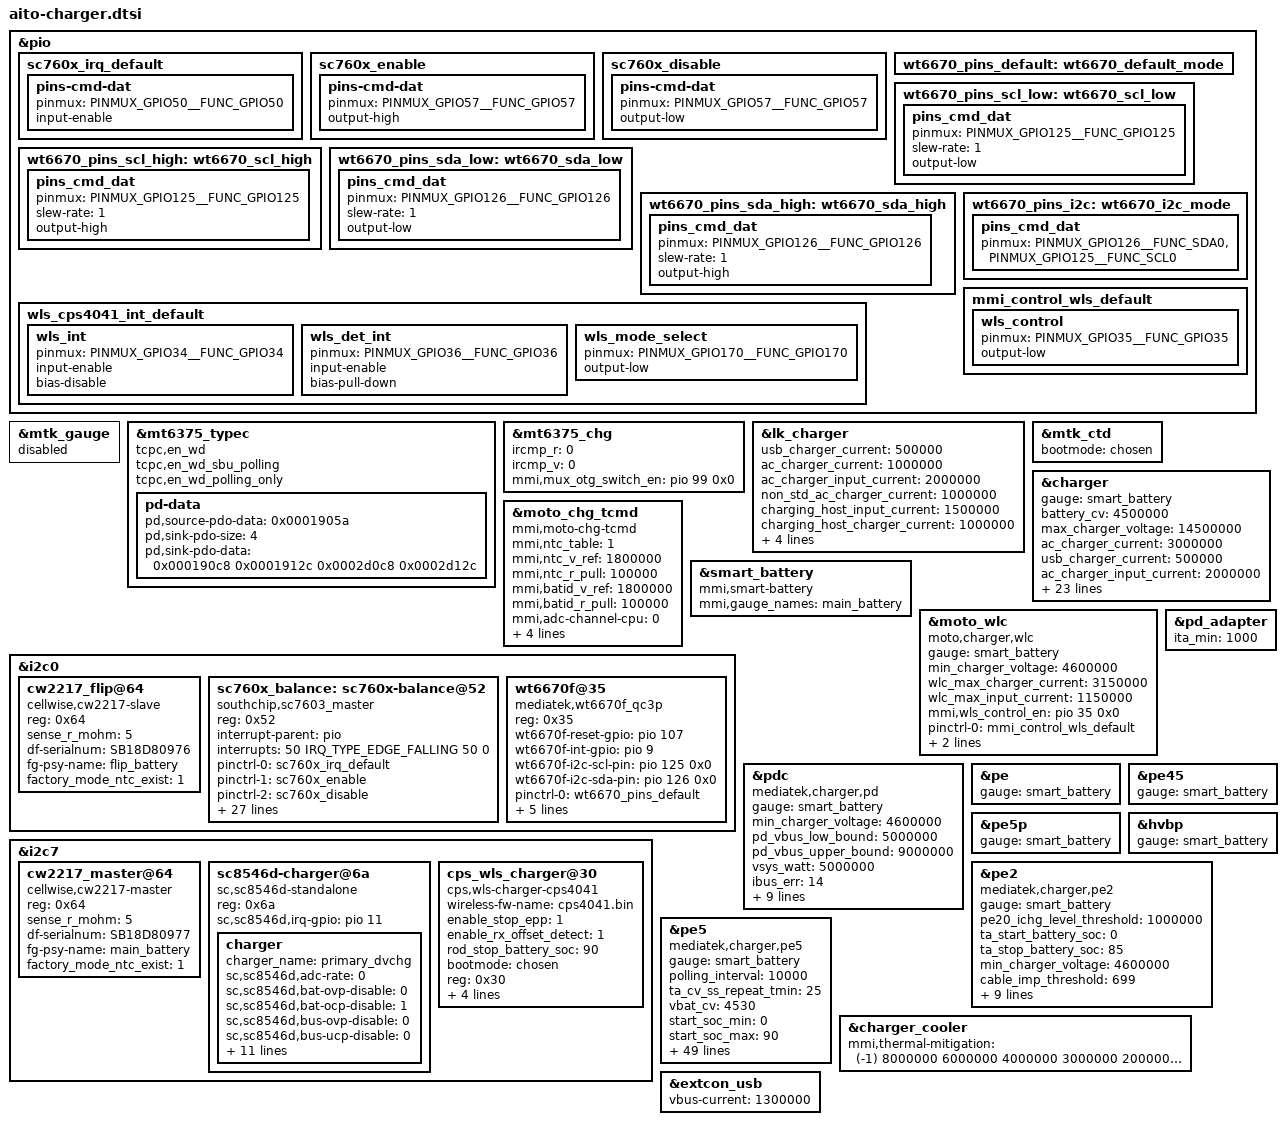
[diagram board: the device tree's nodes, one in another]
/*
 * Copyright (c) 2021 MediaTek Inc.
 *
 * This program is free software; you can redistribute it and/or modify
 * it under the terms of the GNU General Public License version 2 as
 * published by the Free Software Foundation.
 *
 * This program is distributed in the hope that it will be useful,
 * but WITHOUT ANY WARRANTY; without even the implied warranty of
 * MERCHANTABILITY or FITNESS FOR A PARTICULAR PURPOSE.  See the
 * GNU General Public License for more details.
 */
#include <dt-bindings/iio/adc/mediatek,mt6375_auxadc.h>
#include <dt-bindings/iio/adc/mediatek,mt6375_adc.h>
#include <dt-bindings/iio/mt635x-auxadc.h>

&pio {
	sc760x_irq_default: sc760x_irq_default {
		pins-cmd-dat {
			pinmux = <PINMUX_GPIO50__FUNC_GPIO50>;
			input-enable;
		};
	};

	sc760x_enable: sc760x_enable {
		pins-cmd-dat {
			pinmux = <PINMUX_GPIO57__FUNC_GPIO57>;
			output-high;
		};
	};
	sc760x_disable: sc760x_disable {
		pins-cmd-dat {
			pinmux = <PINMUX_GPIO57__FUNC_GPIO57>;
			output-low;
		};
	};

	wt6670_pins_default: wt6670_default_mode {
		};

	wt6670_pins_scl_low: wt6670_scl_low {
		pins_cmd_dat {
			pinmux = <PINMUX_GPIO125__FUNC_GPIO125>;
			slew-rate = <1>;
			output-low;
		};
	};
	wt6670_pins_scl_high: wt6670_scl_high {
		pins_cmd_dat {
			pinmux = <PINMUX_GPIO125__FUNC_GPIO125>;
			slew-rate = <1>;
			output-high;
		};
	};
	wt6670_pins_sda_low: wt6670_sda_low {
		pins_cmd_dat {
			pinmux = <PINMUX_GPIO126__FUNC_GPIO126>;
			slew-rate = <1>;
			output-low;
		};
	};
	wt6670_pins_sda_high: wt6670_sda_high {
		pins_cmd_dat {
			pinmux = <PINMUX_GPIO126__FUNC_GPIO126>;
			slew-rate = <1>;
			output-high;
		};
	};
	wt6670_pins_i2c: wt6670_i2c_mode {
		pins_cmd_dat {
			pinmux = <PINMUX_GPIO126__FUNC_SDA0>,
				<PINMUX_GPIO125__FUNC_SCL0>;
		};
	};

	wls_cps4041_int_default: wls_cps4041_int_default {
		wls_int {
			pinmux = <PINMUX_GPIO34__FUNC_GPIO34>;
			input-enable;
			bias-disable;
		};
		wls_det_int {
			pinmux = <PINMUX_GPIO36__FUNC_GPIO36>;
			input-enable;
			bias-pull-down;
		};
		wls_mode_select {
			pinmux = <PINMUX_GPIO170__FUNC_GPIO170>;
			output-low;
		};
	};

	mmi_control_wls_default: mmi_control_wls_default {
		wls_control {
			pinmux = <PINMUX_GPIO35__FUNC_GPIO35>;
			output-low;
		};
	};
};

&mtk_gauge {
	status = "disabled";
};

&mt6375_typec {
       tcpc,en_wd;
       tcpc,en_wd_sbu_polling;
       tcpc,en_wd_polling_only;
};

&mt6375_chg {
	ircmp_r = <0>;
	ircmp_v = <0>;
};

&lk_charger {
	/* charging current */
	usb_charger_current = <500000>;
	ac_charger_current = <1000000>;
	ac_charger_input_current = <2000000>;
	non_std_ac_charger_current = <1000000>;
	charging_host_input_current = <1500000>;
	charging_host_charger_current = <1000000>;
	pre_charge_current = <400>;

	temp_t4_threshold = <60>;
	boot_battery_voltage = <3500000>;
	/*boot battery voltage when using AC charger*/
	ac_charger_boot_battery_voltage = <3400000>;
};

&mtk_ctd {
	bootmode = <&chosen>;
};

&charger {
	gauge = <&smart_battery>;
	battery_cv = <4500000>;
	max_charger_voltage = <14500000>;
	ac_charger_current = <3000000>;
	usb_charger_current = <500000>;
	ac_charger_input_current = <2000000>;
	charging_host_charger_current = <1500000>;
	/*pe5 && pdc && pe2 && wlc*/
	fast_charging_indicator = <0x10>;
	/*swchg + 1CP*/
	charger_configuration= <3>;

	wireless_factory_max_current = <3000000>;
	wireless_factory_max_input_current = <600000>;

	disable_aicl;

	/* dynamic mivr */
	enable_dynamic_mivr;

	/*mmi config*/
	mmi,typec-rp-max-current = <2000000>;
	mmi,iterm-ma = <461>;
	mmi,mmi-temp-zones = <0 4200 800 0>,
			<10 4250 4000 2000>,
			<15 0 4000 4000>,
			<45 4250 12200 8000>,
			<45 4300 8000 6000>,
			<45 4500 6000 4000>,
			<60 4200 4288 0>;
	mmi,mmi-ffc-zones = <0 4200 461>,
			<10 4500 461>,
			<15 4500 461>,
			<25 4530 772>,
			<35 4530 829>,
			<45 4530 1129>,
			<60 4200 461>;
	mmi,enable-charging-limit;
	mmi,upper-limit-capacity = <65>;
	mmi,lower-limit-capacity = <60>;
	mmi,min-cp-therm-current-ua = <2000000>;

	mmi,pd-pmax-mw = <68000>;
	mmi,pd_vbus_low_bound = <5000000>;
	mmi,pd_vbus_upper_bound = <9000000>;

};

&mt6375_chg {
	mmi,mux_otg_switch_en = <&pio 99 0x0>;
};

&moto_chg_tcmd {
	compatible = "mmi,moto-chg-tcmd";
	status = "okay";

	mmi,ntc_table = <1>;
	mmi,ntc_v_ref = <1800000>;
	mmi,ntc_r_pull = <100000>;

	mmi,batid_v_ref = <1800000>;
	mmi,batid_r_pull = <100000>;

	mmi,adc-channel-cpu = <0>;
	mmi,adc-channel-charger = <2>;
	mmi,adc-channel-pa = <1>;
	mmi,adc-channel-batid = <3>;
	mmi,adc-channel-vbat = <100>;
};

&smart_battery {
	status = "okay";
	compatible = "mmi,smart-battery";
	mmi,gauge_names = "main_battery";
};

&i2c0 {
	status = "okay";
	cw2217_flip@64 {
		compatible = "cellwise,cw2217-slave";
		reg = <0x64>;
		sense_r_mohm = <5>;
		df-serialnum = "SB18D80976";
		//vdd-i2c-supply = <&L18B>;
		fg-psy-name = "flip_battery";
		factory_mode_ntc_exist = <1>;
		#include "bat_setting/CW_LN110X-atl-1165mah.dtsi"
	};

	sc760x_balance: sc760x-balance@52{
		status = "okay";
		compatible = "southchip,sc7603_master";
		reg = <0x52>;
		interrupt-parent = <&pio>;
		interrupts = <50 IRQ_TYPE_EDGE_FALLING 50 0>;
		pinctrl-names = "default", "sc760x_enable", "sc760x_disable";
		pinctrl-0 = <&sc760x_irq_default>;
		pinctrl-1 = <&sc760x_enable>;
		pinctrl-2 = <&sc760x_disable>;

		sc,sc760x,bat-chg-lim-disable = <0>;
		sc,sc760x,bat-chg-lim = <39>; /*50 + val * 50*/
		sc,sc760x,pow-lim-disable = <0>;
		sc,sc760x,ilim-disable = <0>;
		sc,sc760x,load-switch-disable = <0>;
		sc,sc760x,low-power-mode-enable = <0>;
		sc,sc760x,itrichg = <3>; /*12.5 + val * 12.5*/
		sc,sc760x,iprechg = <2>; /*50 + val * 50*/
		sc,sc760x,vfc-chg = <2>; /*2800 + val * 50*/
		sc,sc760x,chg-ovp-disable = <0>;
		sc,sc760x,chg-ovp = <0>; /*0:5.0V 1:5.6V*/
		sc,sc760x,bat-ovp-disable = <1>;
		sc,sc760x,bat-ovp = <14>; /*4000 + val *50*/
		sc,sc760x,chg-ocp-disable = <0>;
		sc,sc760x,chg-ocp = <2>; /*10000 + val * 1000*/
		sc,sc760x,dsg-ocp-disable = <0>;
		sc,sc760x,dsg-ocp = <2>; /*10000 + val * 1000*/
		sc,sc760x,tdie-flt-disable = <0>;
		sc,sc760x,tdie-alm-disable = <1>;
		sc,sc760x,tdie-alm = <9>; /*80 + val * 5*/

		init-charger-disabled;
		iterm-microamp = <200000>;
		ichg-max-microamp = <1700000>;
		vchg-max-microvolt = <4600000>;
		ichg-microamp = <700000>;
		vchg-microvolt = <4400000>;
		chg_name = "sc7603_master";
	};

	wt6670f@35 {
		status = "okay";
		compatible = "mediatek,wt6670f_qc3p";
		reg = <0x35>;
		wt6670f-reset-gpio = <&pio 107 0x0>;
		wt6670f-int-gpio = <&pio 9 0x0>;
		wt6670f-i2c-scl-pin = <&pio 125 0x0>;
		wt6670f-i2c-sda-pin = <&pio 126 0x0>;

		pinctrl-names = "default",
						"wt6670_i2c_scl_low", "wt6670_i2c_scl_high",
						"wt6670_i2c_sda_low", "wt6670_i2c_sda_high",
						"wt6670_i2c";
		pinctrl-0 = <&wt6670_pins_default>;
		pinctrl-1 = <&wt6670_pins_scl_low>;
		pinctrl-2 = <&wt6670_pins_scl_high>;
		pinctrl-3 = <&wt6670_pins_sda_low>;
		pinctrl-4 = <&wt6670_pins_sda_high>;
		pinctrl-5 = <&wt6670_pins_i2c>;
	};
};

&i2c7 {
	status = "okay";

	cw2217_master@64 {
		compatible = "cellwise,cw2217-master";
		reg = <0x64>;
		sense_r_mohm = <5>;
		//vdd-i2c-supply = <&L18B>;;
		df-serialnum = "SB18D80977";
		fg-psy-name = "main_battery";
		factory_mode_ntc_exist = <1>;
		#include "bat_setting/CW_LN110X-atl-2850mah.dtsi"
	};

	sc8546d-charger@6a{
		compatible = "sc,sc8546d-standalone";
		reg = <0x6a>;
		sc,sc8546d,irq-gpio = <&pio 11 IRQ_TYPE_EDGE_FALLING>;
		charger {
		    charger_name = "primary_dvchg";
		    sc,sc8546d,adc-rate = <0>;    /*0:Continuous conversion  1:One-shot*/

		    sc,sc8546d,bat-ovp-disable = <0>;    /*0:enable protetion  1:disable protetion*/
		    sc,sc8546d,bat-ocp-disable = <1>;    /*0:enable protetion  1:disable protetion*/
		    sc,sc8546d,bus-ovp-disable = <0>;    /*0:enable protetion  1:disable protetion*/
		    sc,sc8546d,bus-ucp-disable = <0>;    /*0:enable protetion  1:disable protetion*/
		    sc,sc8546d,bus-ocp-disable = <0>;    /*0:enable protetion  1:disable protetion*/

		    sc,sc8546d,bat-ovp-threshold = <44>;/* val * 25 + 3500 mv [0-63]*/
		    sc,sc8546d,bat-ocp-threshold = <50>;/* val * 100 + 2000 ma [0-63]*/
		    sc,sc8546d,ac-ovp-threshold = <2>;/* val * 1000 + 11000 mv  [0-7] when val = 7 the value = 6500mv*/
		    sc,sc8546d,bus-ovp-threshold = <100>;/* val * 50 + 6000 mv [0-127]*/
		    sc,sc8546d,bus-ocp-threshold = <8>;/* val * 300 + 1200 ma [0-15]*/
		    sc,sc8546d,sense-resistor-mohm = <0>;/*0:5mΩ 1:2mΩ*/

		    sc,sc8546d,ibat-regulation-enable = <0>;/*0:disable 1:enable*/
		    sc,sc8546d,vbat-regulation-enable = <0>;/*0:disable 1:enable*/

		    sc,sc8546d,ibat-regulation-threshold = <1>;/*0:200 mA 1:300 mA 2:400 mA 3:500 mA*/
		    sc,sc8546d,vbat-regulation-threshold = <0>;/*0:50 mV 1:100 mV 2:150 mV 3:200 mV*/
		};
	};

	cps_wls_charger@30 {
		compatible = "cps,wls-charger-cps4041";
		wireless-fw-name = "cps4041.bin";
		enable_stop_epp = <1>;
		enable_rx_offset_detect = <1>;
		/*stop rx offset detect battery soc*/
		rod_stop_battery_soc = <90>;
		bootmode = <&chosen>;
		reg = <0x30>;
		cps_wls_int = <&pio 34 0x0>;
		cps_det_int = <&pio 36 0x0>;
		wls_mode_select = <&pio 170 0x0>;
		pinctrl-names = "default";
		pinctrl-0 = <&wls_cps4041_int_default>;
		status = "okay";
	};
};

&moto_wlc {
	compatible = "moto,charger,wlc";
	gauge = <&smart_battery>;
	min_charger_voltage = <4600000>;
	wlc_max_charger_current = <3150000>;
	wlc_max_input_current = <1150000>;
	mmi,wls_control_en = <&pio 35 0x0>;
	pinctrl-names = "default";
	pinctrl-0 = <&mmi_control_wls_default>;
	#cooling-cells = <2>;
	mmi,wlc-rx-mitigation = <(-1) 2500000 2000000 1500000 1200000
							1000000 800000 500000>;
};

&pd_adapter{
	ita_min = <1000>;
};

&pdc {
	compatible = "mediatek,charger,pd";
	gauge = <&smart_battery>;

	min_charger_voltage = <4600000>;
	pd_vbus_low_bound = <5000000>;
	pd_vbus_upper_bound = <9000000>;
	vsys_watt = <5000000>;
	ibus_err = <14>;

	pd_stop_battery_soc = <80>;

	/* single charger */
	sc_input_current = <3000000>;
	sc_charger_current = <3000000>;

	/* dual charger in series*/
	dcs_input_current = <3200000>;
	dcs_chg1_charger_current = <1500000>;
	dcs_chg2_charger_current = <1500000>;

	/* dual charger */
	dual_polling_ieoc = <450000>;
	slave_mivr_diff = <100000>;
	vbat_threshold = <4150>;
};

&pe {
	gauge = <&smart_battery>;
};

&pe45 {
	gauge = <&smart_battery>;
};

&pe5p {
	gauge = <&smart_battery>;
};

&hvbp {
	gauge = <&smart_battery>;
};

&pe2 {
	compatible = "mediatek,charger,pe2";
	gauge = <&smart_battery>;

	/* PE 2.0 */
	pe20_ichg_level_threshold = <1000000>; /* uA */
	ta_start_battery_soc = <0>;
	ta_stop_battery_soc = <85>;
	min_charger_voltage = <4600000>;

	/* cable measurement impedance */
	cable_imp_threshold = <699>;
	vbat_cable_imp_threshold = <3900000>; /* uV */

	/* single charger */
	sc_input_current = <3000000>;
	sc_charger_current = <3000000>;

	/* dual charger in series*/
	dcs_input_current = <3200000>;
	dcs_chg1_charger_current = <1500000>;
	dcs_chg2_charger_current = <1500000>;

	dual_polling_ieoc = <450000>;
	slave_mivr_diff = <100000>;
	vbat_threshold = <4150>;
};

&pe5 {
	compatible = "mediatek,charger,pe5";
	gauge = <&smart_battery>;
	polling_interval = <10000>;
	ta_cv_ss_repeat_tmin = <25>;
	vbat_cv = <4530>;
	start_soc_min = <0>;
	start_soc_max = <90>;
	start_vbat_max = <4450>;
	idvchg_term = <500>;
	idvchg_step = <50>;
	ita_level = <3000 2000 1500 1000>;
	rcable_level = <230 260 300 480>;
	ita_level_dual = <6200 3000 2000 1500>;
	rcable_level_dual = <180 230 260 300>;
	idvchg_ss_init = <1000>;
	idvchg_ss_step = <250>;
	idvchg_ss_step1 = <100>;
	idvchg_ss_step2 = <50>;
	idvchg_ss_step1_vbat = <4000>;
	idvchg_ss_step2_vbat = <4200>;
	ta_blanking = <400>;
	swchg_aicr = <0>;
	swchg_ichg = <1200>;
	swchg_aicr_ss_init = <400>;
	swchg_aicr_ss_step = <200>;
	swchg_off_vbat = <4250>;
	force_ta_cv_vbat = <4250>;
	chg_time_max = <10800>;
	tta_level_def = <0 0 0 0 25 50 60 70 80>;
	tta_curlmt = <0 0 0 0 0 0 0 0 0>;
	tta_recovery_area = <3>;
	tbat_level_def = <0 0 0 5 25 40 43 46 50>;
	tbat_curlmt = <0 0 0 0 0 0 0 0 0>;
	tbat_recovery_area = <3>;
	tdvchg_level_def = <0 0 0 5 25 55 60 65 70>;
	tdvchg_curlmt = <0 0 0 0 0 0 0 0 0>;
	tdvchg_recovery_area = <3>;
	tswchg_level_def = <0 0 0 5 25 65 70 75 80>;
	tswchg_curlmt = <0 0 0 0 0 0 0 0 0>;
	tswchg_recovery_area = <3>;
	ifod_threshold = <200>;
	rsw_min = <20>;
	ircmp_rbat = <40>;
	ircmp_vclamp = <0>;
	vta_cap_min = <6800>;
	vta_cap_max = <11000>;
	ita_cap_min = <1000>;
	support_ta = "pca_ta_pps", "pd_adapter";
	allow_not_check_ta_status;
	vbat_threshold = <4150>;
	min_charger_voltage = <4600000>;
	mmi_therm_cur_thres = <500>;
	mmi_therm_vol_thres = <80>;
	mmi_therm_step = <3>;
	mmi_max_ibat = <12200>;
	mmi_max_hrst_cnt = <1>;
};

&mt6375_typec {
	pd-data {
		/* 5V, 900ma */
		pd,source-pdo-data = <0x0001905a>;
		/*5V, 2A 5V, 3A  9V, 2A  9V, 3A*/
		pd,sink-pdo-size = <4>;
		pd,sink-pdo-data = <0x000190c8 0x0001912c 0x0002d0c8 0x0002d12c> ;
	};
};


&charger_cooler {
	mmi,thermal-mitigation = <(-1) 8000000 6000000 4000000 3000000
				2000000 1000000 500000 300000>;
};

&extcon_usb {
	vbus-current = <1300000>;
};
